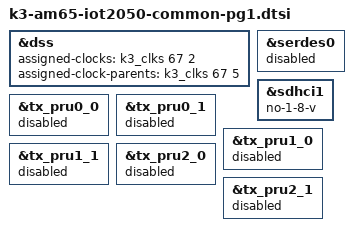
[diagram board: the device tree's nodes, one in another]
// SPDX-License-Identifier: GPL-2.0
/*
 * Copyright (c) Siemens AG, 2021
 *
 * Authors:
 *   Jan Kiszka <jan.kiszka@siemens.com>
 *
 * Common bits of the IOT2050 Basic and Advanced variants, PG1
 */

&dss {
	assigned-clocks = <&k3_clks 67 2>;
	assigned-clock-parents = <&k3_clks 67 5>;
};

&serdes0 {
	status = "disabled";
};

&sdhci1 {
	no-1-8-v;
};

&tx_pru0_0 {
	status = "disabled";
};

&tx_pru0_1 {
	status = "disabled";
};

&tx_pru1_0 {
	status = "disabled";
};

&tx_pru1_1 {
	status = "disabled";
};

&tx_pru2_0 {
	status = "disabled";
};

&tx_pru2_1 {
	status = "disabled";
};
